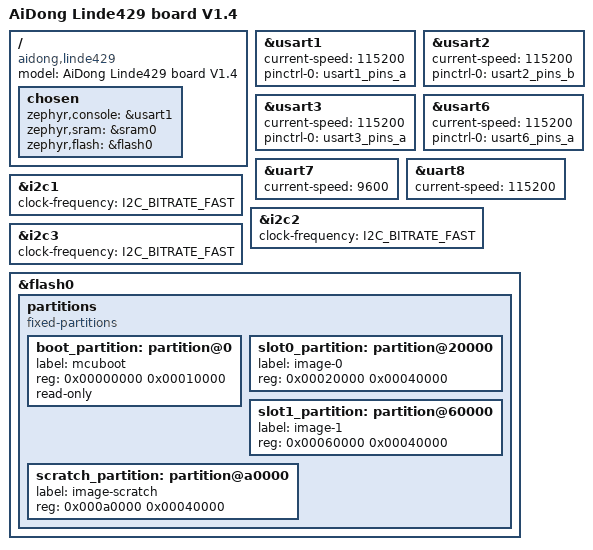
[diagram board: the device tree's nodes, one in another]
/*
 * Copyright (c) 2018 Rainbonic Technology Corporation
 *
 * SPDX-License-Identifier: Apache-2.0
 */

/dts-v1/;
#include <st/stm32f429.dtsi>

/ {
	model = "AiDong Linde429 board V1.4";
	compatible = "aidong,linde429", "st,stm32f429";

	chosen {
		zephyr,console = &usart1;
		zephyr,sram = &sram0;
		zephyr,flash = &flash0;
	};
};

&usart1 {
	current-speed = <115200>;
	pinctrl-0 = <&usart1_pins_a>;
	pinctrl-names = "default";
	status = "ok";
};

&usart2 {
	current-speed = <115200>;
	pinctrl-0 = <&usart2_pins_b>;
	pinctrl-names = "default";
	status = "ok";
};

&usart3 {
	current-speed = <115200>;
	pinctrl-0 = <&usart3_pins_a>;
	pinctrl-names = "default";
	status = "ok";
};

&usart6 {
	current-speed = <115200>;
	pinctrl-0 = <&usart6_pins_a>;
	pinctrl-names = "default";
	status = "ok";
};

&uart7 {
	current-speed = <9600>;
	pinctrl-names = "default";
	status = "ok";
};

&uart8 {
	current-speed = <115200>;
	pinctrl-names = "default";
	status = "ok";
};

&i2c1 {
	status = "ok";
	clock-frequency = <I2C_BITRATE_FAST>;
};

&i2c2 {
	status = "ok";
	clock-frequency = <I2C_BITRATE_FAST>;
};

&i2c3 {
	status = "ok";
	clock-frequency = <I2C_BITRATE_FAST>;
};

&flash0 {
	/*
	 * For more information, see:
	 * http://docs.zephyrproject.org/devices/dts/flash_partitions.html
	 */
	partitions {
		compatible = "fixed-partitions";
		#address-cells = <1>;
		#size-cells = <1>;

		boot_partition: partition@0 {
			label = "mcuboot";
			reg = <0x00000000 0x00010000>;
			read-only;
		};

		/*
		 * The flash starting at offset 0x10000 and ending at
		 * offset 0x1ffff is reserved for use by the application.
		 */

		slot0_partition: partition@20000 {
			label = "image-0";
			reg = <0x00020000 0x00040000>;
		};
		slot1_partition: partition@60000 {
			label = "image-1";
			reg = <0x00060000 0x00040000>;
		};
		scratch_partition: partition@a0000 {
			label = "image-scratch";
			reg = <0x000a0000 0x00040000>;
		};
	};
};
